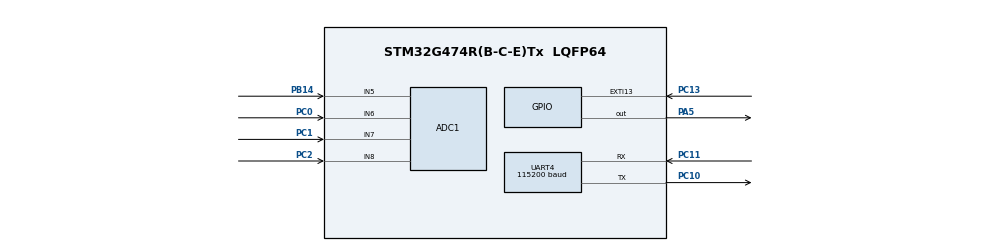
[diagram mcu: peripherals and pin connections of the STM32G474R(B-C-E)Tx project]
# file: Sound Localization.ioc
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ADC1.Channel-0\#ChannelRegularConversion=ADC_CHANNEL_5
ADC1.Channel-1\#ChannelRegularConversion=ADC_CHANNEL_6
ADC1.Channel-2\#ChannelRegularConversion=ADC_CHANNEL_7
ADC1.Channel-3\#ChannelRegularConversion=ADC_CHANNEL_8
ADC1.DMAContinuousRequests=ENABLE
ADC1.EOCSelection=ADC_EOC_SEQ_CONV
ADC1.ExternalTrigConv=ADC_EXTERNALTRIG_T8_TRGO
ADC1.NbrOfConversion=4
ADC1.NbrOfConversionFlag=1
ADC1.OffsetNumber-0\#ChannelRegularConversion=ADC_OFFSET_NONE
ADC1.OffsetNumber-1\#ChannelRegularConversion=ADC_OFFSET_NONE
ADC1.OffsetNumber-2\#ChannelRegularConversion=ADC_OFFSET_NONE
ADC1.OffsetNumber-3\#ChannelRegularConversion=ADC_OFFSET_NONE
ADC1.Rank-0\#ChannelRegularConversion=1
ADC1.Rank-1\#ChannelRegularConversion=2
ADC1.Rank-2\#ChannelRegularConversion=3
ADC1.Rank-3\#ChannelRegularConversion=4
ADC1.SamplingTime-0\#ChannelRegularConversion=ADC_SAMPLETIME_2CYCLES_5
ADC1.SamplingTime-1\#ChannelRegularConversion=ADC_SAMPLETIME_2CYCLES_5
ADC1.SamplingTime-2\#ChannelRegularConversion=ADC_SAMPLETIME_2CYCLES_5
ADC1.SamplingTime-3\#ChannelRegularConversion=ADC_SAMPLETIME_2CYCLES_5
ADC1.master=1
Dma.ADC1.0.Direction=DMA_PERIPH_TO_MEMORY
Dma.ADC1.0.EventEnable=DISABLE
Dma.ADC1.0.Instance=DMA1_Channel1
Dma.ADC1.0.MemDataAlignment=DMA_MDATAALIGN_HALFWORD
Dma.ADC1.0.MemInc=DMA_MINC_ENABLE
Dma.ADC1.0.Mode=DMA_CIRCULAR
Dma.ADC1.0.PeriphDataAlignment=DMA_PDATAALIGN_HALFWORD
Dma.ADC1.0.PeriphInc=DMA_PINC_DISABLE
Dma.ADC1.0.Polarity=HAL_DMAMUX_REQ_GEN_RISING
Dma.ADC1.0.Priority=DMA_PRIORITY_HIGH
Dma.ADC1.0.RequestNumber=1
Dma.ADC1.0.SignalID=NONE
Dma.ADC1.0.SyncEnable=DISABLE
Dma.ADC1.0.SyncPolarity=HAL_DMAMUX_SYNC_NO_EVENT
Dma.ADC1.0.SyncRequestNumber=1
Dma.ADC1.0.SyncSignalID=NONE
Dma.Request0=ADC1
FREERTOS.Queues01=queueXommData,8,uint32_t,0,Dynamic,NULL,NULL;queueResult,4,uint32_t,0,Dynamic,NULL,NULL
FREERTOS.Tasks01=defaultTask,-3,128,StartDefaultTask,Default,NULL,Dynamic,NULL,NULL;ACQ_Task,3,256,StartACQTask,Default,NULL,Dynamic,NULL,NULL;UART_Task,-2,256,StartUARTTask,Default,NULL,Dynamic,NULL,NULL;FFT_Task,2,1024,StartFFTTask,Default,NULL,Dynamic,NULL,NULL
FREERTOS.configENABLE_FPU=1
FREERTOS.configMINIMAL_STACK_SIZE=128
FREERTOS.configTOTAL_HEAP_SIZE=24576
FREERTOS.configUSE_NEWLIB_REENTRANT=1
Mcu.Family=STM32G4
Mcu.Name=STM32G474R(B-C-E)Tx
Mcu.Package=LQFP64
NUCLEO-G474RE.BUTTON=1
NUCLEO-G474RE.LD2=true
NUCLEO-G474RE.VCP=true
NVIC.ADC1_2_IRQn=true\:5\:0\:false\:false\:true\:true\:true\:true\:true
NVIC.DMA1_Channel1_IRQn=true\:5\:0\:false\:false\:true\:true\:false\:true\:true
NVIC.EXTI15_10_IRQn=true\:5\:0\:false\:false\:true\:true\:true\:true\:true
NVIC.PriorityGroup=NVIC_PRIORITYGROUP_4
NVIC.TIM6_DAC_IRQn=true\:15\:0\:false\:false\:true\:false\:false\:true\:true
NVIC.TimeBase=TIM6_DAC_IRQn
NVIC.TimeBaseIP=TIM6
PA13.GPIO_Label=T_SWDIO
PA13.Mode=Serial_Wire
PA13.Signal=SYS_JTMS-SWDIO
PA14.GPIO_Label=T_SWCLK
PA14.Mode=Serial_Wire
PA14.Signal=SYS_JTCK-SWCLK
PA2.Signal=LPUART1_TX
PA3.Signal=LPUART1_RX
PA5.Signal=GPIO_Output
PB14.Mode=IN5-Single-Ended
PB14.Signal=ADC1_IN5
PB3.GPIO_Label=T_SWO
PB3.Signal=SYS_JTDO-SWO
PC0.Mode=IN6-Single-Ended
PC0.Signal=ADC1_IN6
PC1.Mode=IN7-Single-Ended
PC1.Signal=ADC1_IN7
PC10.Mode=Asynchronous
PC10.Signal=UART4_TX
PC11.Mode=Asynchronous
PC11.Signal=UART4_RX
PC13.Signal=GPXTI13
PC14-OSC32_IN.GPIO_Label=RCC_OSC32_IN
PC14-OSC32_IN.Signal=RCC_OSC32_IN
PC15-OSC32_OUT.GPIO_Label=RCC_OSC32_OUT
PC15-OSC32_OUT.Signal=RCC_OSC32_OUT
PC2.Mode=IN8-Single-Ended
PC2.Signal=ADC1_IN8
PF0-OSC_IN.GPIO_Label=RCC_OSC_IN
PF0-OSC_IN.Mode=HSE-External-Oscillator
PF0-OSC_IN.Signal=RCC_OSC_IN
PF1-OSC_OUT.GPIO_Label=RCC_OSC_OUT
PF1-OSC_OUT.Mode=HSE-External-Oscillator
PF1-OSC_OUT.Signal=RCC_OSC_OUT
ProjectManager.HeapSize=0x200
ProjectManager.StackSize=0x400
ProjectManager.TargetToolchain=STM32CubeIDE
RCC.ADC12Freq_Value=170000000
RCC.ADC345Freq_Value=170000000
RCC.AHBFreq_Value=170000000
RCC.APB1Freq_Value=170000000
RCC.APB1TimFreq_Value=170000000
RCC.APB2Freq_Value=170000000
RCC.APB2TimFreq_Value=170000000
RCC.CortexFreq_Value=170000000
RCC.EXTERNAL_CLOCK_VALUE=12288000
RCC.HCLKFreq_Value=170000000
RCC.HSE_VALUE=48000000
RCC.HSI48_VALUE=48000000
RCC.HSI_VALUE=16000000
RCC.LSE_VALUE=32768
RCC.PLLM=RCC_PLLM_DIV4
RCC.PLLN=85
RCC.RTCClockSelection=RCC_RTCCLKSOURCE_LSE
RCC.SYSCLKFreq_VALUE=170000000
RCC.SYSCLKSource=RCC_SYSCLKSOURCE_PLLCLK
RCC.USBFreq_Value=170000000
RCC.VCOOutputFreq_Value=340000000
TIM8.PeriodNoDither=2655
TIM8.TIM_MasterOutputTrigger=TIM_TRGO_UPDATE
UART4.BaudRate=115200
VP_FREERTOS_VS_CMSIS_V1.Mode=CMSIS_V1
VP_NUCLEO-G474RE_VS_BSP_COMMON.Mode=COMMON
VP_SYS_VS_DBSignals.Mode=DisableDeadBatterySignals
VP_SYS_VS_tim6.Mode=TIM6
VP_TIM8_VS_ClockSourceINT.Mode=Internal
board=NUCLEO-G474RE

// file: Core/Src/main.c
/* USER CODE BEGIN Header */
/**
  ******************************************************************************
  * @file    main.c
  * @brief   Startup: periferije → I2C/IMU init → taskovi → scheduler
  ******************************************************************************
  */
/* USER CODE END Header */
#include "main.h"
#include "cmsis_os.h"

/* USER CODE BEGIN Includes */
#include "adc_driver.h"      /* Custom_ACQ_Start */
#include "task_manager.h"    /* app_tasks_init */
#include "app_init.h"        /* app_init (I2C + IMU + dijagnostika) */
/* USER CODE END Includes */

COM_InitTypeDef BspCOMInit;

/* USER CODE BEGIN PV */
/* RTOS taskovi i queue-ovi kreiraju se u task_manager.c (app_tasks_init).
 * I2C se inicijalizira LL driverom (i2c_driver.c), ne HAL handle-om. */
/* USER CODE END PV */

void SystemClock_Config(void);
static void MX_GPIO_Init(void);
static void MX_DMA_Init(void);
static void MX_ADC1_Init(void);
static void MX_UART4_Init(void);
static void MX_TIM8_Init(void);

/* USER CODE BEGIN PFP */
/* I2C1 inicijalizira LL driver (Custom_I2C1_Init iz i2c_driver.c), ne CubeMX —
 * zato ovdje nema MX_I2C1_Init. Taskovi (Start*Task) su u task_manager.c. */

/* USER CODE END PFP */

int main(void)
{

  /* MCU Configuration--------------------------------------------------------*/

  /* Reset of all peripherals, Initializes the Flash interface and the Systick. */
  HAL_Init();

  /* Configure the system clock */
  SystemClock_Config();

  /* Initialize all configured peripherals */
  MX_GPIO_Init();
  MX_DMA_Init();
  MX_ADC1_Init();
  MX_UART4_Init();
  MX_TIM8_Init();
  /* USER CODE BEGIN 2 */
  /* Aplikacijski init (I2C LL + IMU + dijagnostika + kalibracija žira). Lokalizacija
   * (time-domain, LOC_INIT) i RTOS objekti su u task_manageru (app_tasks_init). */
  app_init();
  /* USER CODE END 2 */

  /* USER CODE BEGIN RTOS_THREADS */
  /* Svi queue-ovi i taskovi (ACQ/LOC/UART/IMU) kreiraju se u task_manager.c.
   * Kreiraj RTOS objekte (queueDmaEventHandle i dr.) PRIJE pokretanja ADC/DMA/TIM:
   * DMA1_Channel1_IRQHandler šalje u queueDmaEventHandle, koji nastaje ovdje.
   * Da ISR ne gađa NULL handle, Custom_ACQ_Start() ide tek nakon ovoga. */
  app_tasks_init();
  Custom_ACQ_Start();
  /* USER CODE END RTOS_THREADS */

  /* Initialize led */
  BSP_LED_Init(LED_GREEN);

  /* Initialize USER push-button, will be used to trigger an interrupt each time it's pressed.*/
  BSP_PB_Init(BUTTON_USER, BUTTON_MODE_EXTI);

  /* Initialize COM1 port (115200, 8 bits (7-bit data + 1 stop bit), no parity */
  BspCOMInit.BaudRate   = 115200;
  BspCOMInit.WordLength = COM_WORDLENGTH_8B;
  BspCOMInit.StopBits   = COM_STOPBITS_1;
  BspCOMInit.Parity     = COM_PARITY_NONE;
  BspCOMInit.HwFlowCtl  = COM_HWCONTROL_NONE;
  if (BSP_COM_Init(COM1, &BspCOMInit) != BSP_ERROR_NONE)
  {
    Error_Handler();
  }

  /* Start scheduler */
  osKernelStart();

  /* We should never get here as control is now taken by the scheduler */

  /* Infinite loop */
  while (1)
  {

  }
}

void SystemClock_Config(void)
{
  LL_FLASH_SetLatency(LL_FLASH_LATENCY_4);
  while(LL_FLASH_GetLatency() != LL_FLASH_LATENCY_4)
  {
  }
  LL_PWR_EnableRange1BoostMode();
  LL_RCC_HSI_Enable();
   /* Wait till HSI is ready */
  while(LL_RCC_HSI_IsReady() != 1)
  {
  }

  LL_RCC_HSI_SetCalibTrimming(64);
  LL_RCC_PLL_ConfigDomain_SYS(LL_RCC_PLLSOURCE_HSI, LL_RCC_PLLM_DIV_4, 85, LL_RCC_PLLR_DIV_2);
  LL_RCC_PLL_EnableDomain_SYS();
  LL_RCC_PLL_Enable();
   /* Wait till PLL is ready */
  while(LL_RCC_PLL_IsReady() != 1)
  {
  }

  LL_RCC_SetSysClkSource(LL_RCC_SYS_CLKSOURCE_PLL);
  LL_RCC_SetAHBPrescaler(LL_RCC_SYSCLK_DIV_2);
   /* Wait till System clock is ready */
  while(LL_RCC_GetSysClkSource() != LL_RCC_SYS_CLKSOURCE_STATUS_PLL)
  {
  }

  /* Insure 1us transition state at intermediate medium speed clock*/
  for (__IO uint32_t i = (170 >> 1); i !=0; i--);

  /* Set AHB prescaler*/
  LL_RCC_SetAHBPrescaler(LL_RCC_SYSCLK_DIV_1);
  LL_RCC_SetAPB1Prescaler(LL_RCC_APB1_DIV_1);
  LL_RCC_SetAPB2Prescaler(LL_RCC_APB2_DIV_1);
  LL_SetSystemCoreClock(170000000);

   /* Update the time base */
  if (HAL_InitTick (TICK_INT_PRIORITY) != HAL_OK)
  {
    Error_Handler();
  }
}

static void MX_ADC1_Init(void)
{

  LL_ADC_InitTypeDef ADC_InitStruct = {0};
  LL_ADC_REG_InitTypeDef ADC_REG_InitStruct = {0};
  LL_ADC_CommonInitTypeDef ADC_CommonInitStruct = {0};

  LL_GPIO_InitTypeDef GPIO_InitStruct = {0};

  LL_RCC_SetADCClockSource(LL_RCC_ADC12_CLKSOURCE_SYSCLK);

  /* Peripheral clock enable */
  LL_AHB2_GRP1_EnableClock(LL_AHB2_GRP1_PERIPH_ADC12);

  LL_AHB2_GRP1_EnableClock(LL_AHB2_GRP1_PERIPH_GPIOC);
  LL_AHB2_GRP1_EnableClock(LL_AHB2_GRP1_PERIPH_GPIOB);
  /**ADC1 GPIO Configuration
  PC0   ------> ADC1_IN6
  PC1   ------> ADC1_IN7
  PC2   ------> ADC1_IN8
  PB14   ------> ADC1_IN5
  */
  GPIO_InitStruct.Pin = LL_GPIO_PIN_0;
  GPIO_InitStruct.Mode = LL_GPIO_MODE_ANALOG;
  GPIO_InitStruct.Pull = LL_GPIO_PULL_NO;
  LL_GPIO_Init(GPIOC, &GPIO_InitStruct);

  GPIO_InitStruct.Pin = LL_GPIO_PIN_1;
  GPIO_InitStruct.Mode = LL_GPIO_MODE_ANALOG;
  GPIO_InitStruct.Pull = LL_GPIO_PULL_NO;
  LL_GPIO_Init(GPIOC, &GPIO_InitStruct);

  GPIO_InitStruct.Pin = LL_GPIO_PIN_2;
  GPIO_InitStruct.Mode = LL_GPIO_MODE_ANALOG;
  GPIO_InitStruct.Pull = LL_GPIO_PULL_NO;
  LL_GPIO_Init(GPIOC, &GPIO_InitStruct);

  GPIO_InitStruct.Pin = LL_GPIO_PIN_14;
  GPIO_InitStruct.Mode = LL_GPIO_MODE_ANALOG;
  GPIO_InitStruct.Pull = LL_GPIO_PULL_NO;
  LL_GPIO_Init(GPIOB, &GPIO_InitStruct);

  /* ADC1 DMA Init */

  /* ADC1 Init */
  LL_DMA_SetPeriphRequest(DMA1, LL_DMA_CHANNEL_1, LL_DMAMUX_REQ_ADC1);

  LL_DMA_SetDataTransferDirection(DMA1, LL_DMA_CHANNEL_1, LL_DMA_DIRECTION_PERIPH_TO_MEMORY);

  LL_DMA_SetChannelPriorityLevel(DMA1, LL_DMA_CHANNEL_1, LL_DMA_PRIORITY_HIGH);

  LL_DMA_SetMode(DMA1, LL_DMA_CHANNEL_1, LL_DMA_MODE_CIRCULAR);

  LL_DMA_SetPeriphIncMode(DMA1, LL_DMA_CHANNEL_1, LL_DMA_PERIPH_NOINCREMENT);

  LL_DMA_SetMemoryIncMode(DMA1, LL_DMA_CHANNEL_1, LL_DMA_MEMORY_INCREMENT);

  LL_DMA_SetPeriphSize(DMA1, LL_DMA_CHANNEL_1, LL_DMA_PDATAALIGN_HALFWORD);

  LL_DMA_SetMemorySize(DMA1, LL_DMA_CHANNEL_1, LL_DMA_MDATAALIGN_HALFWORD);

  /* ADC1 interrupt Init */
  NVIC_SetPriority(ADC1_2_IRQn, NVIC_EncodePriority(NVIC_GetPriorityGrouping(),5, 0));
  NVIC_EnableIRQ(ADC1_2_IRQn);

  /** Common config
  */
  ADC_InitStruct.Resolution = LL_ADC_RESOLUTION_12B;
  ADC_InitStruct.DataAlignment = LL_ADC_DATA_ALIGN_RIGHT;
  ADC_InitStruct.LowPowerMode = LL_ADC_LP_MODE_NONE;
  LL_ADC_Init(ADC1, &ADC_InitStruct);
  ADC_REG_InitStruct.TriggerSource = LL_ADC_REG_TRIG_EXT_TIM8_TRGO;
  ADC_REG_InitStruct.SequencerLength = LL_ADC_REG_SEQ_SCAN_ENABLE_4RANKS;
  ADC_REG_InitStruct.SequencerDiscont = LL_ADC_REG_SEQ_DISCONT_DISABLE;
  ADC_REG_InitStruct.ContinuousMode = LL_ADC_REG_CONV_SINGLE;
  ADC_REG_InitStruct.DMATransfer = LL_ADC_REG_DMA_TRANSFER_UNLIMITED;
  ADC_REG_InitStruct.Overrun = LL_ADC_REG_OVR_DATA_PRESERVED;
  LL_ADC_REG_Init(ADC1, &ADC_REG_InitStruct);
  LL_ADC_SetGainCompensation(ADC1, 0);
  LL_ADC_SetOverSamplingScope(ADC1, LL_ADC_OVS_DISABLE);
  ADC_CommonInitStruct.CommonClock = LL_ADC_CLOCK_SYNC_PCLK_DIV4;
  ADC_CommonInitStruct.Multimode = LL_ADC_MULTI_INDEPENDENT;
  LL_ADC_CommonInit(__LL_ADC_COMMON_INSTANCE(ADC1), &ADC_CommonInitStruct);
  LL_ADC_REG_SetTriggerEdge(ADC1, LL_ADC_REG_TRIG_EXT_RISING);

  /* Disable ADC deep power down (enabled by default after reset state) */
  LL_ADC_DisableDeepPowerDown(ADC1);
  /* Enable ADC internal voltage regulator */
  LL_ADC_EnableInternalRegulator(ADC1);
  /* Delay for ADC internal voltage regulator stabilization. */
  /* Compute number of CPU cycles to wait for, from delay in us. */
  /* Note: Variable divided by 2 to compensate partially */
  /* CPU processing cycles (depends on compilation optimization). */
  /* Note: If system core clock frequency is below 200kHz, wait time */
  /* is only a few CPU processing cycles. */
  uint32_t wait_loop_index;
  wait_loop_index = ((LL_ADC_DELAY_INTERNAL_REGUL_STAB_US * (SystemCoreClock / (100000 * 2))) / 10);
  while(wait_loop_index != 0)
  {
    wait_loop_index--;
  }

  /** Configure Regular Channel
  */
  LL_ADC_REG_SetSequencerRanks(ADC1, LL_ADC_REG_RANK_1, LL_ADC_CHANNEL_5);
  LL_ADC_SetChannelSamplingTime(ADC1, LL_ADC_CHANNEL_5, LL_ADC_SAMPLINGTIME_2CYCLES_5);
  LL_ADC_SetChannelSingleDiff(ADC1, LL_ADC_CHANNEL_5, LL_ADC_SINGLE_ENDED);

  /** Configure Regular Channel
  */
  LL_ADC_REG_SetSequencerRanks(ADC1, LL_ADC_REG_RANK_2, LL_ADC_CHANNEL_6);
  LL_ADC_SetChannelSamplingTime(ADC1, LL_ADC_CHANNEL_6, LL_ADC_SAMPLINGTIME_2CYCLES_5);
  LL_ADC_SetChannelSingleDiff(ADC1, LL_ADC_CHANNEL_6, LL_ADC_SINGLE_ENDED);

  /** Configure Regular Channel
  */
  LL_ADC_REG_SetSequencerRanks(ADC1, LL_ADC_REG_RANK_3, LL_ADC_CHANNEL_7);
  LL_ADC_SetChannelSamplingTime(ADC1, LL_ADC_CHANNEL_7, LL_ADC_SAMPLINGTIME_2CYCLES_5);
  LL_ADC_SetChannelSingleDiff(ADC1, LL_ADC_CHANNEL_7, LL_ADC_SINGLE_ENDED);

  /** Configure Regular Channel
  */
  LL_ADC_REG_SetSequencerRanks(ADC1, LL_ADC_REG_RANK_4, LL_ADC_CHANNEL_8);
  LL_ADC_SetChannelSamplingTime(ADC1, LL_ADC_CHANNEL_8, LL_ADC_SAMPLINGTIME_2CYCLES_5);
  LL_ADC_SetChannelSingleDiff(ADC1, LL_ADC_CHANNEL_8, LL_ADC_SINGLE_ENDED);

}

static void MX_TIM8_Init(void)
{

  LL_TIM_InitTypeDef TIM_InitStruct = {0};

  /* Peripheral clock enable */
  LL_APB2_GRP1_EnableClock(LL_APB2_GRP1_PERIPH_TIM8);

  TIM_InitStruct.Prescaler = 0;
  TIM_InitStruct.CounterMode = LL_TIM_COUNTERMODE_UP;
  TIM_InitStruct.Autoreload = 2655;
  TIM_InitStruct.ClockDivision = LL_TIM_CLOCKDIVISION_DIV1;
  TIM_InitStruct.RepetitionCounter = 0;
  LL_TIM_Init(TIM8, &TIM_InitStruct);
  LL_TIM_DisableARRPreload(TIM8);
  LL_TIM_SetClockSource(TIM8, LL_TIM_CLOCKSOURCE_INTERNAL);
  LL_TIM_SetTriggerOutput(TIM8, LL_TIM_TRGO_UPDATE);
  LL_TIM_SetTriggerOutput2(TIM8, LL_TIM_TRGO2_RESET);
  LL_TIM_DisableMasterSlaveMode(TIM8);

}

static void MX_UART4_Init(void)
{

  LL_USART_InitTypeDef USART_InitStruct = {0};

  LL_GPIO_InitTypeDef GPIO_InitStruct = {0};

  LL_RCC_SetUARTClockSource(LL_RCC_UART4_CLKSOURCE_PCLK1);

  /* Peripheral clock enable */
  LL_APB1_GRP1_EnableClock(LL_APB1_GRP1_PERIPH_UART4);

  LL_AHB2_GRP1_EnableClock(LL_AHB2_GRP1_PERIPH_GPIOC);
  /**UART4 GPIO Configuration
  PC10   ------> UART4_TX
  PC11   ------> UART4_RX
  */
  GPIO_InitStruct.Pin = LL_GPIO_PIN_10;
  GPIO_InitStruct.Mode = LL_GPIO_MODE_ALTERNATE;
  GPIO_InitStruct.Speed = LL_GPIO_SPEED_FREQ_LOW;
  GPIO_InitStruct.OutputType = LL_GPIO_OUTPUT_PUSHPULL;
  GPIO_InitStruct.Pull = LL_GPIO_PULL_NO;
  GPIO_InitStruct.Alternate = LL_GPIO_AF_5;
  LL_GPIO_Init(GPIOC, &GPIO_InitStruct);

  GPIO_InitStruct.Pin = LL_GPIO_PIN_11;
  GPIO_InitStruct.Mode = LL_GPIO_MODE_ALTERNATE;
  GPIO_InitStruct.Speed = LL_GPIO_SPEED_FREQ_LOW;
  GPIO_InitStruct.OutputType = LL_GPIO_OUTPUT_PUSHPULL;
  GPIO_InitStruct.Pull = LL_GPIO_PULL_NO;
  GPIO_InitStruct.Alternate = LL_GPIO_AF_5;
  LL_GPIO_Init(GPIOC, &GPIO_InitStruct);

  USART_InitStruct.PrescalerValue = LL_USART_PRESCALER_DIV1;
  USART_InitStruct.BaudRate = 115200;
  USART_InitStruct.DataWidth = LL_USART_DATAWIDTH_8B;
  USART_InitStruct.StopBits = LL_USART_STOPBITS_1;
  USART_InitStruct.Parity = LL_USART_PARITY_NONE;
  USART_InitStruct.TransferDirection = LL_USART_DIRECTION_TX_RX;
  USART_InitStruct.HardwareFlowControl = LL_USART_HWCONTROL_NONE;
  USART_InitStruct.OverSampling = LL_USART_OVERSAMPLING_16;
  LL_USART_Init(UART4, &USART_InitStruct);
  LL_USART_DisableFIFO(UART4);
  LL_USART_SetTXFIFOThreshold(UART4, LL_USART_FIFOTHRESHOLD_1_8);
  LL_USART_SetRXFIFOThreshold(UART4, LL_USART_FIFOTHRESHOLD_1_8);
  LL_USART_ConfigAsyncMode(UART4);

  LL_USART_Enable(UART4);

  /* Polling UART4 initialisation */
  while((!(LL_USART_IsActiveFlag_TEACK(UART4))) || (!(LL_USART_IsActiveFlag_REACK(UART4))))
  {
  }

}

static void MX_DMA_Init(void)
{

  /* Init with LL driver */
  /* DMA controller clock enable */
  LL_AHB1_GRP1_EnableClock(LL_AHB1_GRP1_PERIPH_DMAMUX1);
  LL_AHB1_GRP1_EnableClock(LL_AHB1_GRP1_PERIPH_DMA1);

  /* DMA interrupt init */
  /* DMA1_Channel1_IRQn interrupt configuration */
  NVIC_SetPriority(DMA1_Channel1_IRQn, NVIC_EncodePriority(NVIC_GetPriorityGrouping(),5, 0));
  NVIC_EnableIRQ(DMA1_Channel1_IRQn);

}

static void MX_GPIO_Init(void)
{

  /* GPIO Ports Clock Enable */
  LL_AHB2_GRP1_EnableClock(LL_AHB2_GRP1_PERIPH_GPIOC);
  LL_AHB2_GRP1_EnableClock(LL_AHB2_GRP1_PERIPH_GPIOF);
  LL_AHB2_GRP1_EnableClock(LL_AHB2_GRP1_PERIPH_GPIOB);
  LL_AHB2_GRP1_EnableClock(LL_AHB2_GRP1_PERIPH_GPIOA);

}

/* USER CODE BEGIN 4 */
/* HAL_TIM_PeriodElapsedCallback (TIM6 → HAL_IncTick) generira CubeMX niže. */

void vApplicationStackOverflowHook(TaskHandle_t xTask, char *pcTaskName)
{
  (void)xTask; (void)pcTaskName;
  __disable_irq();
  while (1) {}
}

void vApplicationMallocFailedHook(void)
{
  __disable_irq();
  while (1) {}
}
/* USER CODE END 4 */

/* Taskovi (StartACQTask / StartLOCTask / StartUARTTask / StartIMUTask) i njihove
 * implementacije su u task_manager.c. defaultTask se ne koristi. */

void HAL_TIM_PeriodElapsedCallback(TIM_HandleTypeDef *htim)
{
  if (htim->Instance == TIM6)
  {
    HAL_IncTick();
  }
}

void Error_Handler(void)
{
  __disable_irq();
  while (1)
  {
  }
}
